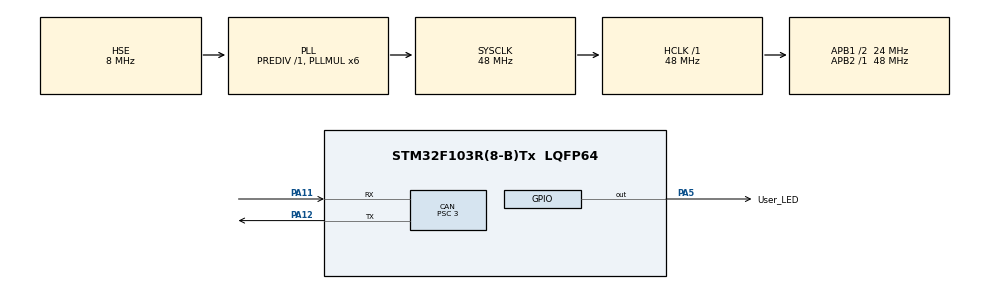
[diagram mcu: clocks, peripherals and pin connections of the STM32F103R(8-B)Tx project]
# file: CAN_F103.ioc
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CAN.ABOM=ENABLE
CAN.AWUM=ENABLE
CAN.BS1=CAN_BS1_13TQ
CAN.BS2=CAN_BS2_2TQ
CAN.CalculateBaudRate=500000
CAN.CalculateTimeBit=2000
CAN.CalculateTimeQuantum=125.0
CAN.Mode=CAN_MODE_NORMAL
CAN.NART=ENABLE
CAN.Prescaler=3
CAN.RFLM=ENABLE
CAN.TXFP=DISABLE
Mcu.Family=STM32F1
Mcu.Name=STM32F103R(8-B)Tx
Mcu.Package=LQFP64
NVIC.CAN1_RX1_IRQn=true\:0\:0\:false\:false\:true\:true\:true
NVIC.PriorityGroup=NVIC_PRIORITYGROUP_4
NVIC.USB_HP_CAN1_TX_IRQn=true\:0\:0\:false\:false\:true\:true\:true
NVIC.USB_LP_CAN1_RX0_IRQn=true\:0\:0\:false\:false\:true\:true\:true
PA11.Mode=CAN_Activate
PA11.Signal=CAN_RX
PA12.Mode=CAN_Activate
PA12.Signal=CAN_TX
PA13.Mode=Serial_Wire
PA13.Signal=SYS_JTMS-SWDIO
PA14.Mode=Serial_Wire
PA14.Signal=SYS_JTCK-SWCLK
PA5.GPIO_Label=User_LED
PA5.GPIO_ModeDefaultOutputPP=GPIO_MODE_OUTPUT_PP
PA5.GPIO_PuPd=GPIO_NOPULL
PA5.Signal=GPIO_Output
PD0-OSC_IN.Mode=HSE-External-Oscillator
PD0-OSC_IN.Signal=RCC_OSC_IN
PD1-OSC_OUT.Mode=HSE-External-Oscillator
PD1-OSC_OUT.Signal=RCC_OSC_OUT
ProjectManager.HeapSize=0x200
ProjectManager.StackSize=0x400
ProjectManager.TargetToolchain=STM32CubeIDE
RCC.AHBFreq_Value=48000000
RCC.APB1CLKDivider=RCC_HCLK_DIV2
RCC.APB1Freq_Value=24000000
RCC.APB1TimFreq_Value=48000000
RCC.APB2Freq_Value=48000000
RCC.APB2TimFreq_Value=48000000
RCC.HCLKFreq_Value=48000000
RCC.PLLMUL=RCC_PLL_MUL6
RCC.PLLSourceVirtual=RCC_PLLSOURCE_HSE
RCC.SYSCLKFreq_VALUE=48000000
RCC.SYSCLKSource=RCC_SYSCLKSOURCE_PLLCLK
RCC.USBFreq_Value=48000000
TIM1.Period=0xffff-1
TIM1.Prescaler=48-1
VP_TIM1_VS_ClockSourceINT.Mode=Internal
board=custom

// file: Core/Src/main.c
/* USER CODE BEGIN Header */
/**
  ******************************************************************************
  * @file           : main.c
  * @brief          : Main program body
  ******************************************************************************
  * @attention
  *
  * <h2><center>&copy; Copyright (c) 2021 STMicroelectronics.
  * All rights reserved.</center></h2>
  *
  * This software component is licensed by ST under BSD 3-Clause license,
  * the "License"; You may not use this file except in compliance with the
  * License. You may obtain a copy of the License at:
  *                        opensource.org/licenses/BSD-3-Clause
  *
  ******************************************************************************
  */
/* USER CODE END Header */
#include "main.h"

/* USER CODE BEGIN Includes */
#include "stdio.h"

/* USER CODE END Includes */

CAN_HandleTypeDef hcan;

TIM_HandleTypeDef htim1;

/* USER CODE BEGIN PV */

CAN_FilterTypeDef sFilterConfig;
CAN_TxHeaderTypeDef TxHeader;
CAN_RxHeaderTypeDef RxHeader;
uint16_t TxData[4] = {0, 0, 0, 0};
uint16_t RxData[4] = {0, 0, 0, 0};
uint32_t TxMailbox;

/* USER CODE END PV */

void SystemClock_Config(void);
static void MX_GPIO_Init(void);
static void MX_TIM1_Init(void);
static void MX_CAN_Init(void);
/* USER CODE BEGIN PFP */
static uint32_t BufferCmp8b(uint8_t* pBuffer1, uint8_t* pBuffer2, uint16_t BufferLength);
/* USER CODE END PFP */

int main(void)
{

  /* MCU Configuration--------------------------------------------------------*/

  /* Reset of all peripherals, Initializes the Flash interface and the Systick. */
  HAL_Init();

  /* Configure the system clock */
  SystemClock_Config();

  /* Initialize all configured peripherals */
  MX_GPIO_Init();
  MX_TIM1_Init();
  MX_CAN_Init();
  /* USER CODE BEGIN 2 */

	// Timer start
	HAL_TIM_Base_Start(&htim1);

	// CAN filter parameters
	sFilterConfig.FilterIdHigh = 456 << 5;
	sFilterConfig.FilterIdLow = 0x0000;
	sFilterConfig.FilterMaskIdHigh = 0xFFFF;
	sFilterConfig.FilterMaskIdLow = 0x0000;
	sFilterConfig.FilterFIFOAssignment = CAN_FILTER_FIFO0;
	sFilterConfig.FilterBank = 10;
	sFilterConfig.FilterMode = CAN_FILTERMODE_IDMASK;
	sFilterConfig.FilterScale = CAN_FILTERSCALE_32BIT;
	sFilterConfig.FilterActivation = CAN_FILTER_ENABLE;
	sFilterConfig.SlaveStartFilterBank = 0;

	// CAN TX header parameters
	TxHeader.StdId = 1365;
	TxHeader.ExtId = 123;
	TxHeader.RTR = CAN_RTR_DATA;
	TxHeader.IDE = CAN_ID_STD;
	TxHeader.DLC = 8;
	TxHeader.TransmitGlobalTime = DISABLE;

	// apply CAN filter configuration
	if (HAL_CAN_ConfigFilter(&hcan, &sFilterConfig) != HAL_OK)
	{
	  /* Filter configuration Error */
	  Error_Handler();
	}

	// start CAN bus operation
	if (HAL_CAN_Start(&hcan) != HAL_OK)
	{
	  /* Start Error */
	  Error_Handler();
	}

	HAL_CAN_ActivateNotification(&hcan, CAN_IT_RX_FIFO0_MSG_PENDING);

	// Data array filling
	TxData[0] = 12;
	TxData[1] = 34;
	TxData[2] = 56;
	TxData[3] = 78;

  /* USER CODE END 2 */

  /* Infinite loop */
	while (1)
	{

    /* USER CODE BEGIN 3 */

	// Send message on CAN TX
	HAL_CAN_AddTxMessage(&hcan, &TxHeader, (uint8_t *) TxData, &TxMailbox);

	// 30 minutes delay
	HAL_Delay(1000);

  }
  /* USER CODE END 3 */
}

void SystemClock_Config(void)
{
  RCC_OscInitTypeDef RCC_OscInitStruct = {0};
  RCC_ClkInitTypeDef RCC_ClkInitStruct = {0};

  /** Initializes the RCC Oscillators according to the specified parameters
  * in the RCC_OscInitTypeDef structure.
  */
  RCC_OscInitStruct.OscillatorType = RCC_OSCILLATORTYPE_HSE;
  RCC_OscInitStruct.HSEState = RCC_HSE_ON;
  RCC_OscInitStruct.HSEPredivValue = RCC_HSE_PREDIV_DIV1;
  RCC_OscInitStruct.HSIState = RCC_HSI_ON;
  RCC_OscInitStruct.PLL.PLLState = RCC_PLL_ON;
  RCC_OscInitStruct.PLL.PLLSource = RCC_PLLSOURCE_HSE;
  RCC_OscInitStruct.PLL.PLLMUL = RCC_PLL_MUL6;
  if (HAL_RCC_OscConfig(&RCC_OscInitStruct) != HAL_OK)
  {
    Error_Handler();
  }
  /** Initializes the CPU, AHB and APB buses clocks
  */
  RCC_ClkInitStruct.ClockType = RCC_CLOCKTYPE_HCLK|RCC_CLOCKTYPE_SYSCLK
                              |RCC_CLOCKTYPE_PCLK1|RCC_CLOCKTYPE_PCLK2;
  RCC_ClkInitStruct.SYSCLKSource = RCC_SYSCLKSOURCE_PLLCLK;
  RCC_ClkInitStruct.AHBCLKDivider = RCC_SYSCLK_DIV1;
  RCC_ClkInitStruct.APB1CLKDivider = RCC_HCLK_DIV2;
  RCC_ClkInitStruct.APB2CLKDivider = RCC_HCLK_DIV1;

  if (HAL_RCC_ClockConfig(&RCC_ClkInitStruct, FLASH_LATENCY_1) != HAL_OK)
  {
    Error_Handler();
  }
}

static void MX_CAN_Init(void)
{

  hcan.Instance = CAN1;
  hcan.Init.Prescaler = 3;
  hcan.Init.Mode = CAN_MODE_NORMAL;
  hcan.Init.SyncJumpWidth = CAN_SJW_1TQ;
  hcan.Init.TimeSeg1 = CAN_BS1_13TQ;
  hcan.Init.TimeSeg2 = CAN_BS2_2TQ;
  hcan.Init.TimeTriggeredMode = DISABLE;
  hcan.Init.AutoBusOff = ENABLE;
  hcan.Init.AutoWakeUp = ENABLE;
  hcan.Init.AutoRetransmission = ENABLE;
  hcan.Init.ReceiveFifoLocked = ENABLE;
  hcan.Init.TransmitFifoPriority = DISABLE;
  if (HAL_CAN_Init(&hcan) != HAL_OK)
  {
    Error_Handler();
  }

}

static void MX_TIM1_Init(void)
{

  TIM_ClockConfigTypeDef sClockSourceConfig = {0};
  TIM_MasterConfigTypeDef sMasterConfig = {0};

  htim1.Instance = TIM1;
  htim1.Init.Prescaler = 48-1;
  htim1.Init.CounterMode = TIM_COUNTERMODE_UP;
  htim1.Init.Period = 0xffff-1;
  htim1.Init.ClockDivision = TIM_CLOCKDIVISION_DIV1;
  htim1.Init.RepetitionCounter = 0;
  htim1.Init.AutoReloadPreload = TIM_AUTORELOAD_PRELOAD_DISABLE;
  if (HAL_TIM_Base_Init(&htim1) != HAL_OK)
  {
    Error_Handler();
  }
  sClockSourceConfig.ClockSource = TIM_CLOCKSOURCE_INTERNAL;
  if (HAL_TIM_ConfigClockSource(&htim1, &sClockSourceConfig) != HAL_OK)
  {
    Error_Handler();
  }
  sMasterConfig.MasterOutputTrigger = TIM_TRGO_RESET;
  sMasterConfig.MasterSlaveMode = TIM_MASTERSLAVEMODE_DISABLE;
  if (HAL_TIMEx_MasterConfigSynchronization(&htim1, &sMasterConfig) != HAL_OK)
  {
    Error_Handler();
  }

}

static void MX_GPIO_Init(void)
{
  GPIO_InitTypeDef GPIO_InitStruct = {0};

  /* GPIO Ports Clock Enable */
  __HAL_RCC_GPIOD_CLK_ENABLE();
  __HAL_RCC_GPIOA_CLK_ENABLE();

  /*Configure GPIO pin Output Level */
  HAL_GPIO_WritePin(User_LED_GPIO_Port, User_LED_Pin, GPIO_PIN_RESET);

  /*Configure GPIO pin : User_LED_Pin */
  GPIO_InitStruct.Pin = User_LED_Pin;
  GPIO_InitStruct.Mode = GPIO_MODE_OUTPUT_PP;
  GPIO_InitStruct.Pull = GPIO_NOPULL;
  GPIO_InitStruct.Speed = GPIO_SPEED_FREQ_LOW;
  HAL_GPIO_Init(User_LED_GPIO_Port, &GPIO_InitStruct);

}

/* USER CODE BEGIN 4 */

void HAL_CAN_RxFifo0MsgPendingCallback(CAN_HandleTypeDef *hcan)
{
	HAL_CAN_GetRxMessage(hcan, CAN_RX_FIFO0, &RxHeader, (uint8_t *) RxData);
	if (BufferCmp8b((uint8_t*)TxData, (uint8_t*)RxData, 8) == 0) {
		HAL_GPIO_TogglePin(User_LED_GPIO_Port, User_LED_Pin);
	}
}

static uint32_t BufferCmp8b(uint8_t* pBuffer1, uint8_t* pBuffer2, uint16_t BufferLength)
{
  while(BufferLength--)
  {
    if(*pBuffer1 != *pBuffer2)
    {
      return 1;
    }

    pBuffer1++;
    pBuffer2++;
  }
  return 0;
}

/* USER CODE END 4 */

void Error_Handler(void)
{
  /* USER CODE BEGIN Error_Handler_Debug */
  /* User can add his own implementation to report the HAL error return state */
	HAL_NVIC_SystemReset();
  /* USER CODE END Error_Handler_Debug */
}
